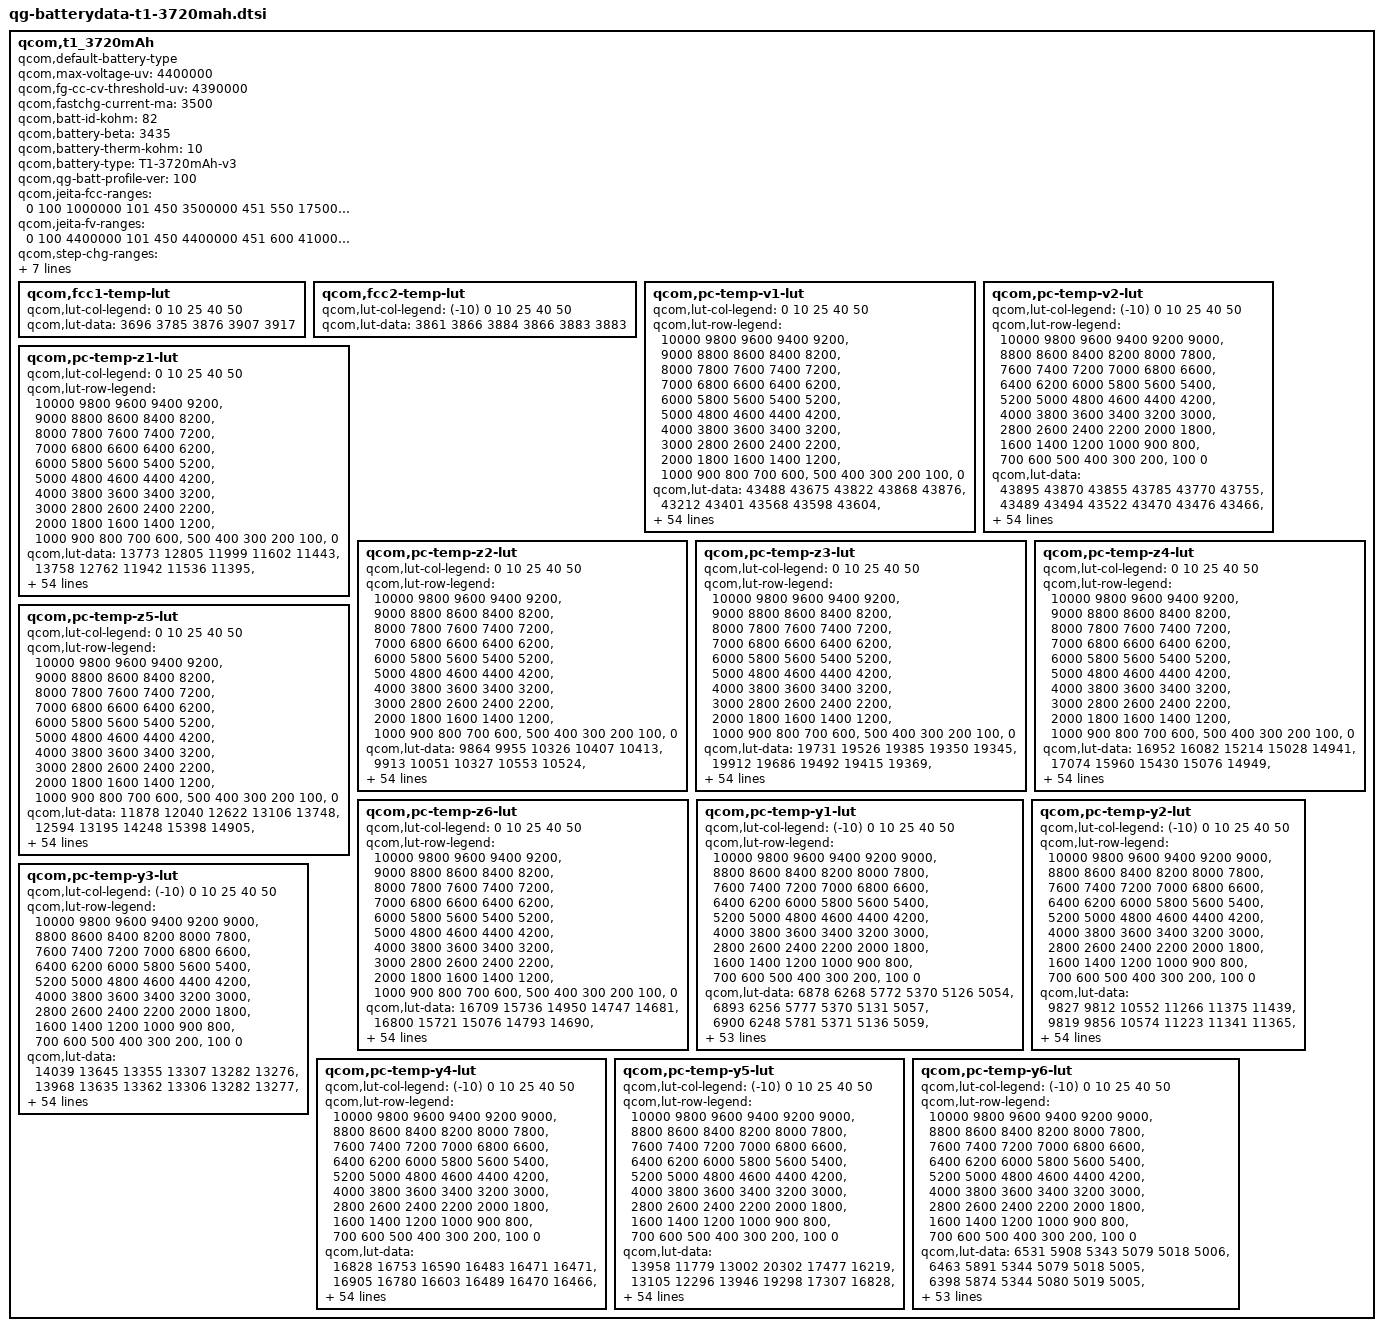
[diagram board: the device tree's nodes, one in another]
/*
 * Copyright (c) 2018, The Linux Foundation. All rights reserved.
 *
 * This program is free software; you can redistribute it and/or modify
 * it under the terms of the GNU General Public License version 2 and
 * only version 2 as published by the Free Software Foundation.
 *
 * This program is distributed in the hope that it will be useful,
 * but WITHOUT ANY WARRANTY; without even the implied warranty of
 * MERCHANTABILITY or FITNESS FOR A PARTICULAR PURPOSE.  See the
 * GNU General Public License for more details.
 */

qcom,t1_3720mAh {
	/* 4059676_TCL_T1_Veken_3820mAH_PM6150_averaged_MasterSlave_Jul23th2019 */
	qcom,default-battery-type;
	qcom,max-voltage-uv = <4400000>;
	qcom,fg-cc-cv-threshold-uv = <4390000>;
	qcom,fastchg-current-ma = <3500>;
	qcom,batt-id-kohm = <82>;
	qcom,battery-beta = <3435>;
	qcom,battery-therm-kohm = <10>;
	qcom,battery-type = "T1-3720mAh-v3";
	qcom,qg-batt-profile-ver = <100>;

	qcom,jeita-fcc-ranges = <0  100   1000000
				101  450  3500000
				451 550  1750000
				551 600  0>;
	qcom,jeita-fv-ranges = <0   100   4400000
				101  450  4400000
				451 600  4100000>;
	qcom,step-chg-ranges = <2800000  4285000  3500000
				4285001  4400000  2500000>;
	qcom,ocv-based-step-chg;

	/* COOL = 10 DegC, WARM = 45 DegC */
	qcom,jeita-soft-thresholds = <0x2aee 0xfb3>;
	/* COLD = 0 DegC, HOT = 55 DegC */
	qcom,jeita-hard-thresholds = <0x3733 0xbc2>;
	/* COOL hys = 13 DegC, WARM hys = 42 DegC */
	qcom,jeita-soft-hys-thresholds = <0x279a 0x1124>;

	qcom,jeita-soft-fcc-ua = <1500000 1500000>;
	qcom,jeita-soft-fv-uv = <4100000 4100000>;

	qcom,fcc1-temp-lut {
		qcom,lut-col-legend = <0 10 25 40 50>;
		qcom,lut-data = <3696 3785 3876 3907 3917>;
	};

	qcom,fcc2-temp-lut {
		qcom,lut-col-legend = <(-10) 0 10 25 40 50>;
		qcom,lut-data = <3861 3866 3884 3866 3883 3883>;
	};

	qcom,pc-temp-v1-lut {
		qcom,lut-col-legend = <0 10 25 40 50>;
		qcom,lut-row-legend = <10000 9800 9600 9400 9200>,
			<9000 8800 8600 8400 8200>,
			<8000 7800 7600 7400 7200>,
			<7000 6800 6600 6400 6200>,
			<6000 5800 5600 5400 5200>,
			<5000 4800 4600 4400 4200>,
			<4000 3800 3600 3400 3200>,
			<3000 2800 2600 2400 2200>,
			<2000 1800 1600 1400 1200>,
			<1000 900 800 700 600>,
			<500 400 300 200 100>,
			<0>;
		qcom,lut-data = <43488 43675 43822 43868 43876>,
			<43212 43401 43568 43598 43604>,
			<42961 43139 43318 43352 43358>,
			<42725 42893 43073 43115 43121>,
			<42495 42658 42830 42879 42885>,
			<42272 42426 42589 42641 42648>,
			<42054 42196 42352 42405 42414>,
			<41840 41973 42118 42169 42181>,
			<41632 41756 41889 41935 41950>,
			<41435 41545 41661 41706 41722>,
			<41261 41350 41438 41479 41495>,
			<41082 41179 41232 41259 41273>,
			<40859 40997 41049 41044 41054>,
			<40588 40755 40857 40836 40843>,
			<40333 40467 40609 40628 40638>,
			<40107 40227 40344 40424 40440>,
			<39907 40035 40147 40233 40250>,
			<39752 39872 40002 40058 40070>,
			<39631 39740 39864 39891 39897>,
			<39518 39629 39720 39735 39736>,
			<39399 39508 39571 39585 39585>,
			<39283 39372 39392 39400 39404>,
			<39169 39229 39179 39139 39145>,
			<39057 39074 38973 38899 38901>,
			<38949 38906 38764 38747 38754>,
			<38845 38746 38581 38629 38643>,
			<38745 38583 38484 38528 38541>,
			<38651 38446 38424 38441 38446>,
			<38563 38362 38367 38361 38357>,
			<38483 38302 38306 38281 38269>,
			<38413 38258 38249 38207 38187>,
			<38350 38229 38194 38140 38116>,
			<38297 38205 38142 38082 38056>,
			<38253 38177 38094 38028 37998>,
			<38216 38150 38053 37981 37944>,
			<38177 38121 38013 37936 37892>,
			<38139 38091 37978 37891 37839>,
			<38098 38056 37944 37847 37786>,
			<38049 38004 37894 37790 37721>,
			<37993 37925 37807 37707 37638>,
			<37918 37831 37701 37606 37539>,
			<37801 37716 37590 37497 37430>,
			<37665 37580 37462 37370 37303>,
			<37508 37416 37302 37212 37145>,
			<37355 37267 37153 37065 37001>,
			<37240 37165 37063 36974 36913>,
			<37206 37139 37036 36950 36892>,
			<37178 37116 37024 36935 36877>,
			<37150 37094 37005 36918 36859>,
			<37116 37062 36968 36876 36809>,
			<36957 36892 36759 36648 36563>,
			<36524 36466 36337 36221 36133>,
			<35951 35902 35770 35650 35561>,
			<35180 35132 34989 34866 34777>,
			<33966 33932 33771 33650 33562>,
			<30000 30000 30000 30000 30000>;
	};

	qcom,pc-temp-v2-lut {
		qcom,lut-col-legend = <(-10) 0 10 25 40 50>;
		qcom,lut-row-legend = <10000 9800 9600 9400 9200 9000>,
			<8800 8600 8400 8200 8000 7800>,
			<7600 7400 7200 7000 6800 6600>,
			<6400 6200 6000 5800 5600 5400>,
			<5200 5000 4800 4600 4400 4200>,
			<4000 3800 3600 3400 3200 3000>,
			<2800 2600 2400 2200 2000 1800>,
			<1600 1400 1200 1000 900 800>,
			<700 600 500 400 300 200>,
			<100 0>;
		qcom,lut-data = <43895 43870 43855 43785 43770 43755>,
			<43489 43494 43522 43470 43476 43466>,
			<43125 43153 43216 43177 43200 43194>,
			<42810 42855 42942 42911 42942 42939>,
			<42534 42592 42698 42670 42704 42702>,
			<42282 42344 42459 42434 42469 42469>,
			<42058 42105 42218 42199 42235 42235>,
			<41845 41873 41982 41968 42003 42004>,
			<41604 41639 41755 41742 41774 41776>,
			<41337 41400 41535 41521 41548 41550>,
			<41131 41195 41325 41304 41326 41327>,
			<41020 41046 41129 41091 41110 41109>,
			<40912 40899 40937 40880 40897 40895>,
			<40647 40683 40741 40671 40692 40690>,
			<40145 40394 40541 40463 40491 40490>,
			<39768 40106 40312 40264 40298 40297>,
			<39569 39815 40020 40069 40110 40109>,
			<39409 39553 39741 39888 39930 39929>,
			<39247 39374 39553 39736 39764 39763>,
			<39094 39237 39403 39604 39608 39607>,
			<38946 39090 39236 39437 39428 39429>,
			<38800 38921 39042 39189 39206 39215>,
			<38662 38757 38860 38938 38988 39004>,
			<38532 38619 38706 38758 38801 38814>,
			<38410 38494 38568 38607 38632 38639>,
			<38306 38374 38447 38479 38496 38500>,
			<38219 38253 38340 38370 38386 38390>,
			<38143 38151 38240 38273 38289 38292>,
			<38073 38080 38140 38184 38199 38201>,
			<38009 38022 38045 38102 38118 38118>,
			<37949 37969 37968 38029 38046 38043>,
			<37891 37920 37902 37959 37981 37973>,
			<37835 37873 37850 37897 37917 37909>,
			<37778 37826 37809 37841 37850 37851>,
			<37723 37782 37775 37792 37783 37793>,
			<37668 37736 37741 37740 37712 37712>,
			<37615 37691 37708 37688 37638 37603>,
			<37561 37642 37669 37631 37560 37500>,
			<37503 37584 37617 37566 37481 37412>,
			<37444 37517 37554 37495 37399 37329>,
			<37385 37439 37477 37414 37316 37247>,
			<37326 37340 37381 37319 37228 37165>,
			<37264 37236 37262 37204 37115 37053>,
			<37195 37133 37122 37066 36980 36916>,
			<37108 37039 36985 36928 36849 36791>,
			<36996 36951 36900 36873 36807 36753>,
			<36931 36912 36874 36857 36795 36741>,
			<36865 36873 36848 36842 36782 36729>,
			<36783 36824 36811 36815 36757 36703>,
			<36645 36733 36729 36746 36678 36609>,
			<36408 36516 36519 36494 36379 36292>,
			<36007 36090 36071 36013 35881 35794>,
			<35411 35465 35433 35386 35236 35146>,
			<34537 34583 34550 34535 34349 34256>,
			<33123 33197 33220 33227 32993 32912>,
			<29037 28523 28866 28088 28343 28620>;
	};

	qcom,pc-temp-z1-lut {
		qcom,lut-col-legend = <0 10 25 40 50>;
		qcom,lut-row-legend = <10000 9800 9600 9400 9200>,
			<9000 8800 8600 8400 8200>,
			<8000 7800 7600 7400 7200>,
			<7000 6800 6600 6400 6200>,
			<6000 5800 5600 5400 5200>,
			<5000 4800 4600 4400 4200>,
			<4000 3800 3600 3400 3200>,
			<3000 2800 2600 2400 2200>,
			<2000 1800 1600 1400 1200>,
			<1000 900 800 700 600>,
			<500 400 300 200 100>,
			<0>;
		qcom,lut-data = <13773 12805 11999 11602 11443>,
			<13758 12762 11942 11536 11395>,
			<13745 12734 11919 11526 11387>,
			<13732 12733 11903 11519 11383>,
			<13732 12733 11896 11512 11378>,
			<13740 12729 11891 11503 11373>,
			<13735 12700 11885 11497 11370>,
			<13709 12674 11875 11494 11370>,
			<13676 12672 11869 11493 11371>,
			<13661 12675 11870 11492 11371>,
			<13662 12677 11873 11494 11371>,
			<13666 12673 11877 11496 11371>,
			<13664 12664 11884 11499 11373>,
			<13653 12643 11887 11503 11376>,
			<13638 12614 11875 11504 11379>,
			<13594 12605 11854 11504 11381>,
			<13543 12605 11850 11505 11383>,
			<13527 12608 11860 11508 11387>,
			<13525 12620 11870 11511 11391>,
			<13524 12642 11878 11515 11393>,
			<13510 12651 11885 11519 11394>,
			<13487 12651 11888 11522 11395>,
			<13483 12651 11891 11523 11395>,
			<13490 12658 11894 11525 11396>,
			<13495 12675 11897 11526 11396>,
			<13492 12683 11901 11528 11398>,
			<13486 12680 11904 11530 11400>,
			<13483 12677 11908 11535 11403>,
			<13501 12677 11910 11540 11407>,
			<13523 12680 11911 11543 11410>,
			<13525 12684 11912 11547 11413>,
			<13516 12695 11917 11551 11416>,
			<13511 12707 11927 11556 11418>,
			<13529 12709 11934 11560 11421>,
			<13560 12707 11937 11563 11424>,
			<13571 12708 11941 11566 11427>,
			<13573 12724 11945 11569 11428>,
			<13576 12745 11950 11571 11428>,
			<13596 12747 11955 11573 11428>,
			<13631 12742 11963 11576 11429>,
			<13642 12740 11970 11578 11431>,
			<13617 12741 11974 11580 11431>,
			<13603 12746 11975 11581 11432>,
			<13605 12769 11979 11581 11431>,
			<13588 12770 11979 11582 11430>,
			<13686 12758 11991 11583 11431>,
			<13900 12780 11987 11581 11429>,
			<13619 12776 11987 11583 11429>,
			<13868 12768 11975 11583 11430>,
			<13611 12774 11976 11585 11432>,
			<13612 12770 11985 11590 11436>,
			<13634 12824 12002 11598 11443>,
			<13625 12818 12017 11607 11451>,
			<13702 12834 12028 11623 11463>,
			<13702 12834 12028 11623 11463>,
			<13702 12834 12028 11623 11463>;
	};

	qcom,pc-temp-z2-lut {
		qcom,lut-col-legend = <0 10 25 40 50>;
		qcom,lut-row-legend = <10000 9800 9600 9400 9200>,
			<9000 8800 8600 8400 8200>,
			<8000 7800 7600 7400 7200>,
			<7000 6800 6600 6400 6200>,
			<6000 5800 5600 5400 5200>,
			<5000 4800 4600 4400 4200>,
			<4000 3800 3600 3400 3200>,
			<3000 2800 2600 2400 2200>,
			<2000 1800 1600 1400 1200>,
			<1000 900 800 700 600>,
			<500 400 300 200 100>,
			<0>;
		qcom,lut-data = <9864 9955 10326 10407 10413>,
			<9913 10051 10327 10553 10524>,
			<9974 10095 10329 10564 10644>,
			<10027 10084 10318 10555 10631>,
			<10039 10059 10295 10531 10610>,
			<10034 10046 10260 10457 10553>,
			<10027 10041 10229 10407 10507>,
			<10012 10036 10194 10410 10505>,
			<9988 10027 10173 10420 10510>,
			<9973 10015 10177 10427 10512>,
			<9967 10009 10189 10440 10511>,
			<9960 10007 10203 10452 10511>,
			<9939 10004 10222 10465 10522>,
			<9892 9990 10244 10481 10535>,
			<9861 9965 10268 10497 10524>,
			<9851 9957 10292 10512 10478>,
			<9846 9972 10307 10515 10453>,
			<9848 9995 10317 10472 10450>,
			<9864 10029 10326 10433 10453>,
			<9881 10073 10332 10442 10468>,
			<9894 10088 10339 10475 10501>,
			<9905 10084 10353 10512 10561>,
			<9908 10079 10387 10564 10748>,
			<9903 10085 10405 10598 10910>,
			<9898 10102 10375 10531 10803>,
			<9898 10109 10334 10395 10535>,
			<9898 10105 10320 10377 10461>,
			<9899 10101 10312 10499 10543>,
			<9906 10106 10310 10598 10619>,
			<9918 10125 10354 10621 10638>,
			<9929 10137 10406 10635 10648>,
			<9938 10140 10402 10619 10634>,
			<9950 10143 10377 10533 10547>,
			<9966 10150 10368 10485 10492>,
			<9986 10160 10372 10519 10525>,
			<10011 10172 10378 10573 10589>,
			<10049 10184 10385 10607 10657>,
			<10074 10196 10398 10632 10741>,
			<10034 10209 10417 10660 10795>,
			<9943 10222 10459 10704 10829>,
			<9912 10238 10491 10736 10848>,
			<9948 10260 10493 10730 10810>,
			<9975 10286 10494 10715 10728>,
			<9989 10309 10505 10727 10757>,
			<9968 10473 10574 10740 10749>,
			<10000 10658 10643 10672 10639>,
			<9727 10607 10641 10664 10650>,
			<9606 10627 10724 10645 10614>,
			<9741 10652 10856 10640 10653>,
			<9627 10720 10809 10731 10778>,
			<9633 10711 10819 10814 10615>,
			<9571 10592 10833 10686 10450>,
			<9768 10438 10888 10617 10357>,
			<9636 10298 10860 10517 10290>,
			<9636 10298 10860 10517 10290>,
			<9636 10298 10860 10517 10290>;
	};

	qcom,pc-temp-z3-lut {
		qcom,lut-col-legend = <0 10 25 40 50>;
		qcom,lut-row-legend = <10000 9800 9600 9400 9200>,
			<9000 8800 8600 8400 8200>,
			<8000 7800 7600 7400 7200>,
			<7000 6800 6600 6400 6200>,
			<6000 5800 5600 5400 5200>,
			<5000 4800 4600 4400 4200>,
			<4000 3800 3600 3400 3200>,
			<3000 2800 2600 2400 2200>,
			<2000 1800 1600 1400 1200>,
			<1000 900 800 700 600>,
			<500 400 300 200 100>,
			<0>;
		qcom,lut-data = <19731 19526 19385 19350 19345>,
			<19912 19686 19492 19415 19369>,
			<19924 19776 19533 19450 19414>,
			<19914 19792 19555 19462 19432>,
			<19895 19800 19565 19467 19442>,
			<19851 19802 19571 19469 19447>,
			<19822 19799 19572 19470 19450>,
			<19827 19793 19567 19467 19444>,
			<19840 19786 19561 19461 19430>,
			<19846 19774 19553 19452 19418>,
			<19846 19761 19542 19439 19409>,
			<19846 19741 19529 19427 19402>,
			<19863 19728 19512 19417 19396>,
			<19927 19733 19503 19408 19389>,
			<19969 19747 19503 19403 19380>,
			<19976 19751 19503 19400 19369>,
			<19976 19728 19500 19396 19361>,
			<19965 19692 19480 19388 19355>,
			<19928 19652 19465 19380 19350>,
			<19896 19608 19461 19376 19347>,
			<19882 19595 19459 19372 19344>,
			<19873 19612 19464 19372 19344>,
			<19872 19637 19486 19391 19361>,
			<19886 19661 19499 19408 19377>,
			<19904 19687 19495 19398 19367>,
			<19914 19698 19488 19377 19341>,
			<19923 19699 19479 19368 19334>,
			<19926 19700 19467 19365 19335>,
			<19923 19699 19462 19364 19339>,
			<19917 19696 19464 19381 19358>,
			<19910 19691 19468 19407 19390>,
			<19897 19680 19475 19412 19395>,
			<19881 19666 19487 19412 19387>,
			<19856 19655 19491 19411 19377>,
			<19824 19644 19488 19405 19370>,
			<19794 19634 19484 19395 19364>,
			<19770 19622 19478 19390 19360>,
			<19736 19612 19470 19386 19357>,
			<19623 19608 19466 19383 19356>,
			<19438 19607 19463 19380 19355>,
			<19372 19604 19461 19377 19354>,
			<19375 19588 19457 19375 19353>,
			<19376 19569 19452 19373 19350>,
			<19372 19560 19448 19371 19350>,
			<19353 19509 19438 19366 19348>,
			<19345 19445 19413 19356 19340>,
			<19298 19338 19413 19355 19333>,
			<19276 19313 19365 19348 19329>,
			<19298 19304 19344 19345 19326>,
			<19271 19303 19355 19338 19317>,
			<19270 19317 19379 19329 19336>,
			<19278 19324 19378 19337 19343>,
			<19351 19318 19343 19339 19348>,
			<19358 19315 19327 19340 19348>,
			<19358 19315 19327 19340 19348>,
			<19358 19315 19327 19340 19348>;
	};

	qcom,pc-temp-z4-lut {
		qcom,lut-col-legend = <0 10 25 40 50>;
		qcom,lut-row-legend = <10000 9800 9600 9400 9200>,
			<9000 8800 8600 8400 8200>,
			<8000 7800 7600 7400 7200>,
			<7000 6800 6600 6400 6200>,
			<6000 5800 5600 5400 5200>,
			<5000 4800 4600 4400 4200>,
			<4000 3800 3600 3400 3200>,
			<3000 2800 2600 2400 2200>,
			<2000 1800 1600 1400 1200>,
			<1000 900 800 700 600>,
			<500 400 300 200 100>,
			<0>;
		qcom,lut-data = <16952 16082 15214 15028 14941>,
			<17074 15960 15430 15076 14949>,
			<16901 15822 15321 15080 14979>,
			<16560 15650 15174 15000 14926>,
			<16309 15465 15081 14942 14881>,
			<16128 15327 15006 14902 14846>,
			<15970 15222 14950 14868 14817>,
			<15827 15139 14907 14832 14796>,
			<15701 15077 14872 14801 14780>,
			<15593 15027 14841 14787 14770>,
			<15501 14983 14814 14781 14763>,
			<15420 14941 14796 14774 14756>,
			<15348 14905 14781 14766 14748>,
			<15284 14872 14770 14757 14739>,
			<15233 14844 14767 14747 14734>,
			<15195 14833 14765 14736 14729>,
			<15163 14830 14759 14726 14724>,
			<15133 14828 14739 14717 14717>,
			<15104 14831 14721 14708 14709>,
			<15075 14837 14711 14702 14702>,
			<15042 14838 14704 14698 14695>,
			<15007 14804 14708 14701 14696>,
			<14970 14769 14735 14761 14754>,
			<14929 14767 14768 14826 14822>,
			<14894 14770 14829 14855 14850>,
			<14869 14775 14890 14875 14869>,
			<14850 14815 14893 14878 14871>,
			<14838 14856 14875 14864 14855>,
			<14831 14857 14853 14844 14829>,
			<14827 14843 14829 14807 14787>,
			<14823 14827 14801 14760 14735>,
			<14819 14809 14773 14732 14712>,
			<14817 14790 14742 14713 14701>,
			<14819 14775 14724 14705 14697>,
			<14825 14763 14714 14703 14698>,
			<14830 14753 14708 14702 14700>,
			<14836 14745 14703 14703 14703>,
			<14847 14739 14700 14706 14709>,
			<14940 14733 14699 14710 14716>,
			<15129 14727 14710 14722 14723>,
			<15197 14725 14720 14731 14728>,
			<15177 14732 14715 14727 14724>,
			<15150 14738 14708 14717 14715>,
			<15122 14735 14708 14720 14717>,
			<15028 14733 14700 14715 14713>,
			<14983 14751 14684 14691 14690>,
			<15026 14868 14670 14678 14682>,
			<15042 14886 14708 14663 14664>,
			<15013 14890 14720 14646 14642>,
			<15033 14885 14704 14652 14648>,
			<15027 14875 14702 14699 14668>,
			<15044 14887 14714 14700 14670>,
			<14995 14905 14760 14701 14666>,
			<15011 14921 14784 14704 14668>,
			<15011 14921 14784 14704 14668>,
			<15011 14921 14784 14704 14668>;
	};

	qcom,pc-temp-z5-lut {
		qcom,lut-col-legend = <0 10 25 40 50>;
		qcom,lut-row-legend = <10000 9800 9600 9400 9200>,
			<9000 8800 8600 8400 8200>,
			<8000 7800 7600 7400 7200>,
			<7000 6800 6600 6400 6200>,
			<6000 5800 5600 5400 5200>,
			<5000 4800 4600 4400 4200>,
			<4000 3800 3600 3400 3200>,
			<3000 2800 2600 2400 2200>,
			<2000 1800 1600 1400 1200>,
			<1000 900 800 700 600>,
			<500 400 300 200 100>,
			<0>;
		qcom,lut-data = <11878 12040 12622 13106 13748>,
			<12594 13195 14248 15398 14905>,
			<12906 13971 14941 16123 16223>,
			<13096 14321 15450 16487 17109>,
			<13193 14556 15958 16721 17789>,
			<13272 14855 16434 16897 18433>,
			<13357 15240 16807 17127 18794>,
			<13523 15589 17111 17753 18764>,
			<13758 15848 17413 18490 18621>,
			<13893 16067 18005 18550 18505>,
			<13939 16282 18746 18202 18292>,
			<13985 16461 19021 17983 18220>,
			<14181 16725 19097 17962 18291>,
			<14723 18073 19208 17978 18315>,
			<15159 20666 20188 18225 18197>,
			<15427 21541 21660 18927 17859>,
			<15642 20508 21775 19389 17716>,
			<15593 18989 20798 19706 17940>,
			<15167 17523 20201 20131 18299>,
			<14854 15992 21009 20576 18674>,
			<14952 15621 23115 21132 19416>,
			<15262 17551 28920 22845 20992>,
			<15760 21085 44150 32356 28056>,
			<16995 27959 52105 40239 34440>,
			<18680 39576 46833 35443 30648>,
			<20591 44857 38370 24637 20794>,
			<22883 45454 32152 19713 16713>,
			<24825 45620 26183 17570 15615>,
			<26656 44898 23205 16682 15157>,
			<28088 42670 22268 17852 17061>,
			<28448 39996 21780 20395 21015>,
			<28327 36399 22905 23209 23309>,
			<27903 32758 26895 26924 24741>,
			<26038 30539 30549 29520 25987>,
			<23012 28906 33985 30878 27557>,
			<20886 27633 36235 31693 28851>,
			<19499 26427 35985 31594 28836>,
			<18029 25589 34876 30835 28026>,
			<15450 26096 33856 29706 26896>,
			<12348 28363 33005 27000 24792>,
			<11328 29548 32052 24196 22647>,
			<11400 26011 30575 23118 21616>,
			<11488 23093 28819 22430 20927>,
			<11575 23320 27451 21305 20455>,
			<11912 21782 27541 21031 20134>,
			<12074 17218 24599 21150 20025>,
			<11528 12520 25447 21843 18949>,
			<11333 11990 16266 21212 19772>,
			<11522 11835 14309 22752 23084>,
			<11307 11841 15395 20669 19858>,
			<11369 12191 17347 15379 17887>,
			<11442 12228 16179 15084 17462>,
			<11971 11959 13623 14774 17720>,
			<11867 11766 12690 14514 16872>,
			<11867 11766 12690 14514 16872>,
			<11867 11766 12690 14514 16872>;
	};

	qcom,pc-temp-z6-lut {
		qcom,lut-col-legend = <0 10 25 40 50>;
		qcom,lut-row-legend = <10000 9800 9600 9400 9200>,
			<9000 8800 8600 8400 8200>,
			<8000 7800 7600 7400 7200>,
			<7000 6800 6600 6400 6200>,
			<6000 5800 5600 5400 5200>,
			<5000 4800 4600 4400 4200>,
			<4000 3800 3600 3400 3200>,
			<3000 2800 2600 2400 2200>,
			<2000 1800 1600 1400 1200>,
			<1000 900 800 700 600>,
			<500 400 300 200 100>,
			<0>;
		qcom,lut-data = <16709 15736 14950 14747 14681>,
			<16800 15721 15076 14793 14690>,
			<16707 15695 15043 14806 14719>,
			<16514 15628 14993 14780 14708>,
			<16361 15525 14956 14759 14697>,
			<16238 15447 14922 14743 14686>,
			<16136 15386 14895 14727 14674>,
			<16059 15336 14872 14710 14661>,
			<15997 15296 14852 14693 14647>,
			<15940 15263 14833 14681 14637>,
			<15884 15231 14816 14672 14629>,
			<15837 15197 14802 14663 14622>,
			<15811 15168 14788 14654 14614>,
			<15794 15150 14778 14646 14607>,
			<15778 15137 14772 14639 14600>,
			<15758 15123 14768 14632 14593>,
			<15735 15107 14760 14625 14586>,
			<15707 15091 14744 14617 14579>,
			<15671 15075 14731 14610 14574>,
			<15637 15060 14726 14605 14569>,
			<15607 15055 14724 14602 14565>,
			<15580 15055 14728 14604 14566>,
			<15569 15054 14750 14643 14603>,
			<15564 15059 14774 14677 14639>,
			<15561 15076 14800 14680 14640>,
			<15560 15095 14821 14680 14638>,
			<15559 15116 14821 14680 14635>,
			<15558 15132 14808 14673 14630>,
			<15557 15132 14796 14665 14623>,
			<15556 15127 14787 14659 14617>,
			<15553 15119 14780 14653 14611>,
			<15547 15108 14773 14646 14605>,
			<15539 15095 14767 14639 14596>,
			<15530 15085 14762 14633 14589>,
			<15520 15076 14758 14628 14585>,
			<15512 15069 14754 14624 14583>,
			<15505 15064 14750 14622 14582>,
			<15499 15060 14745 14621 14583>,
			<15492 15060 14745 14621 14584>,
			<15486 15061 14750 14624 14586>,
			<15482 15062 14754 14627 14588>,
			<15480 15061 14752 14625 14585>,
			<15477 15059 14747 14619 14580>,
			<15470 15058 14748 14619 14581>,
			<15430 15039 14742 14615 14578>,
			<15408 15018 14724 14600 14564>,
			<15405 15013 14718 14594 14557>,
			<15402 15009 14710 14584 14546>,
			<15401 15007 14705 14575 14534>,
			<15403 15008 14706 14574 14534>,
			<15412 15018 14719 14591 14553>,
			<15432 15034 14728 14598 14559>,
			<15456 15050 14734 14601 14563>,
			<15489 15069 14743 14607 14567>,
			<15489 15069 14743 14607 14567>,
			<15489 15069 14743 14607 14567>;
	};

	qcom,pc-temp-y1-lut {
		qcom,lut-col-legend = <(-10) 0 10 25 40 50>;
		qcom,lut-row-legend = <10000 9800 9600 9400 9200 9000>,
			<8800 8600 8400 8200 8000 7800>,
			<7600 7400 7200 7000 6800 6600>,
			<6400 6200 6000 5800 5600 5400>,
			<5200 5000 4800 4600 4400 4200>,
			<4000 3800 3600 3400 3200 3000>,
			<2800 2600 2400 2200 2000 1800>,
			<1600 1400 1200 1000 900 800>,
			<700 600 500 400 300 200>,
			<100 0>;
		qcom,lut-data = <6878 6268 5772 5370 5126 5054>,
			<6893 6256 5777 5370 5131 5057>,
			<6900 6248 5781 5371 5136 5059>,
			<6900 6242 5784 5371 5139 5061>,
			<6897 6239 5786 5370 5142 5061>,
			<6893 6238 5786 5369 5143 5061>,
			<6883 6241 5780 5366 5143 5060>,
			<6870 6246 5773 5363 5142 5059>,
			<6865 6247 5774 5361 5140 5058>,
			<6867 6247 5781 5361 5138 5058>,
			<6870 6247 5784 5361 5137 5058>,
			<6872 6246 5775 5361 5137 5056>,
			<6873 6244 5763 5362 5137 5055>,
			<6876 6246 5765 5360 5136 5055>,
			<6880 6248 5775 5357 5135 5055>,
			<6885 6250 5781 5355 5135 5055>,
			<6896 6251 5785 5363 5137 5055>,
			<6907 6251 5788 5371 5140 5056>,
			<6901 6251 5787 5371 5140 5056>,
			<6879 6252 5783 5369 5140 5056>,
			<6864 6255 5783 5368 5140 5057>,
			<6858 6265 5788 5370 5140 5058>,
			<6853 6273 5791 5371 5141 5058>,
			<6855 6268 5787 5371 5142 5059>,
			<6865 6255 5783 5371 5143 5060>,
			<6875 6244 5781 5373 5145 5061>,
			<6892 6232 5780 5376 5146 5062>,
			<6905 6223 5780 5379 5148 5064>,
			<6885 6218 5783 5381 5150 5066>,
			<6843 6215 5786 5382 5152 5068>,
			<6831 6216 5786 5384 5155 5070>,
			<6841 6225 5782 5388 5158 5072>,
			<6851 6232 5781 5391 5160 5074>,
			<6853 6230 5783 5393 5163 5076>,
			<6854 6225 5788 5395 5165 5077>,
			<6854 6222 5791 5396 5166 5079>,
			<6840 6216 5790 5395 5168 5080>,
			<6826 6210 5788 5394 5170 5080>,
			<6820 6224 5788 5394 5171 5080>,
			<6815 6244 5788 5393 5172 5080>,
			<6819 6241 5786 5394 5173 5081>,
			<6834 6217 5785 5398 5173 5083>,
			<6833 6217 5788 5403 5175 5084>,
			<6824 6228 5801 5409 5177 5087>,
			<6875 6244 5805 5416 5181 5090>,
			<6932 6265 5816 5427 5185 5091>,
			<6897 6247 5817 5423 5188 5093>,
			<6875 6258 5819 5423 5188 5092>,
			<6884 6270 5799 5432 5188 5092>,
			<6931 6269 5813 5433 5190 5091>,
			<6939 6289 5804 5431 5189 5093>,
			<6879 6292 5836 5436 5194 5099>,
			<6905 6289 5837 5462 5202 5105>,
			<6974 6315 5854 5484 5216 5115>,
			<6974 6315 5854 5484 5216 5115>,
			<6974 6315 5854 5484 5216 5115>;
	};

	qcom,pc-temp-y2-lut {
		qcom,lut-col-legend = <(-10) 0 10 25 40 50>;
		qcom,lut-row-legend = <10000 9800 9600 9400 9200 9000>,
			<8800 8600 8400 8200 8000 7800>,
			<7600 7400 7200 7000 6800 6600>,
			<6400 6200 6000 5800 5600 5400>,
			<5200 5000 4800 4600 4400 4200>,
			<4000 3800 3600 3400 3200 3000>,
			<2800 2600 2400 2200 2000 1800>,
			<1600 1400 1200 1000 900 800>,
			<700 600 500 400 300 200>,
			<100 0>;
		qcom,lut-data = <9827 9812 10552 11266 11375 11439>,
			<9819 9856 10574 11223 11341 11365>,
			<9828 9905 10589 11182 11292 11288>,
			<9849 9953 10599 11143 11239 11217>,
			<9881 9993 10604 11108 11196 11164>,
			<9920 10018 10606 11077 11173 11139>,
			<9967 10030 10599 11049 11165 11138>,
			<10027 10040 10591 11024 11159 11145>,
			<10107 10075 10594 11008 11154 11147>,
			<10217 10164 10608 10995 11147 11151>,
			<10303 10260 10618 10991 11144 11149>,
			<10363 10363 10621 10993 11144 11143>,
			<10403 10447 10624 11000 11147 11139>,
			<10295 10469 10670 11023 11155 11147>,
			<9903 10476 10788 11078 11176 11171>,
			<9705 10489 10833 11108 11208 11197>,
			<9691 10522 10822 11111 11281 11227>,
			<9684 10570 10812 11113 11356 11271>,
			<9680 10643 10825 11138 11403 11390>,
			<9678 10742 10862 11190 11442 11579>,
			<9677 10784 10886 11207 11452 11635>,
			<9676 10790 10898 11186 11445 11623>,
			<9675 10793 10910 11166 11433 11602>,
			<9674 10789 10929 11169 11379 11513>,
			<9672 10771 10952 11182 11295 11371>,
			<9671 10701 10974 11196 11278 11349>,
			<9670 10195 10999 11213 11311 11426>,
			<9669 9743 11015 11234 11357 11483>,
			<9669 9707 11017 11261 11412 11510>,
			<9668 9697 11016 11290 11474 11560>,
			<9668 9692 11019 11299 11518 11607>,
			<9667 9689 11024 11300 11558 11657>,
			<9667 9686 11027 11300 11575 11687>,
			<9666 9683 11010 11300 11573 11715>,
			<9665 9681 10980 11298 11566 11744>,
			<9664 9678 10956 11292 11547 11715>,
			<9664 9675 10935 11271 11485 11580>,
			<9663 9672 10910 11252 11443 11469>,
			<9662 9670 10882 11242 11442 11401>,
			<9662 9668 10848 11234 11441 11357>,
			<9662 9666 10802 11221 11426 11366>,
			<9661 9665 10740 11199 11402 11414>,
			<9661 9663 10672 11169 11397 11402>,
			<9660 9662 10450 11121 11385 11336>,
			<9660 9661 9923 11074 11228 11205>,
			<9660 9661 9786 11070 11175 11022>,
			<9659 9660 9733 11046 11176 11048>,
			<9659 9659 9702 11030 11168 11103>,
			<9658 9658 9693 11012 11168 11101>,
			<9658 9658 9684 10996 11169 11123>,
			<9658 9658 9678 10977 11169 10998>,
			<9657 9657 9670 10894 11103 10927>,
			<9656 9656 9664 10791 10996 10911>,
			<9654 9655 9659 10723 10942 10836>,
			<9654 9655 9659 10723 10942 10836>,
			<9654 9655 9659 10723 10942 10836>;
	};

	qcom,pc-temp-y3-lut {
		qcom,lut-col-legend = <(-10) 0 10 25 40 50>;
		qcom,lut-row-legend = <10000 9800 9600 9400 9200 9000>,
			<8800 8600 8400 8200 8000 7800>,
			<7600 7400 7200 7000 6800 6600>,
			<6400 6200 6000 5800 5600 5400>,
			<5200 5000 4800 4600 4400 4200>,
			<4000 3800 3600 3400 3200 3000>,
			<2800 2600 2400 2200 2000 1800>,
			<1600 1400 1200 1000 900 800>,
			<700 600 500 400 300 200>,
			<100 0>;
		qcom,lut-data = <14039 13645 13355 13307 13282 13276>,
			<13968 13635 13362 13306 13282 13277>,
			<13896 13624 13370 13305 13283 13279>,
			<13827 13612 13377 13305 13284 13280>,
			<13770 13598 13384 13305 13285 13281>,
			<13729 13585 13388 13305 13286 13283>,
			<13705 13566 13390 13306 13288 13284>,
			<13686 13550 13391 13307 13289 13285>,
			<13656 13548 13391 13310 13290 13287>,
			<13616 13548 13390 13314 13291 13288>,
			<13579 13548 13390 13317 13292 13289>,
			<13545 13501 13394 13317 13296 13290>,
			<13520 13445 13399 13317 13300 13290>,
			<13516 13443 13395 13317 13301 13292>,
			<13519 13456 13383 13315 13301 13297>,
			<13520 13462 13379 13314 13301 13298>,
			<13514 13450 13379 13315 13300 13297>,
			<13506 13434 13380 13317 13300 13296>,
			<13500 13426 13379 13319 13299 13296>,
			<13494 13422 13374 13322 13295 13297>,
			<13492 13415 13369 13322 13292 13296>,
			<13495 13398 13362 13318 13292 13291>,
			<13499 13384 13355 13312 13291 13285>,
			<13493 13385 13351 13308 13288 13281>,
			<13476 13387 13347 13305 13285 13278>,
			<13470 13386 13345 13303 13283 13278>,
			<13476 13367 13343 13303 13283 13278>,
			<13486 13346 13342 13302 13282 13279>,
			<13495 13343 13339 13303 13283 13279>,
			<13506 13348 13335 13304 13283 13278>,
			<13518 13352 13332 13305 13285 13278>,
			<13532 13360 13327 13305 13287 13278>,
			<13549 13368 13325 13305 13288 13278>,
			<13567 13377 13329 13305 13288 13280>,
			<13587 13394 13335 13306 13287 13282>,
			<13613 13411 13340 13307 13287 13282>,
			<13648 13428 13346 13307 13287 13280>,
			<13686 13448 13350 13307 13286 13279>,
			<13721 13473 13352 13306 13286 13278>,
			<13757 13503 13354 13305 13286 13278>,
			<13799 13533 13356 13305 13286 13279>,
			<13851 13562 13357 13306 13286 13283>,
			<13905 13596 13358 13307 13287 13283>,
			<13958 13638 13358 13306 13287 13281>,
			<13985 13672 13353 13304 13283 13279>,
			<13950 13667 13368 13305 13287 13285>,
			<14003 13713 13387 13307 13289 13287>,
			<14075 13770 13407 13312 13295 13293>,
			<14142 13832 13431 13317 13302 13296>,
			<14208 13892 13449 13324 13304 13295>,
			<14289 13946 13468 13320 13297 13288>,
			<14392 14025 13503 13319 13294 13288>,
			<14538 14137 13593 13331 13302 13294>,
			<14959 14268 13762 13344 13308 13300>,
			<14959 14268 13762 13344 13308 13300>,
			<14959 14268 13762 13344 13308 13300>;
	};

	qcom,pc-temp-y4-lut {
		qcom,lut-col-legend = <(-10) 0 10 25 40 50>;
		qcom,lut-row-legend = <10000 9800 9600 9400 9200 9000>,
			<8800 8600 8400 8200 8000 7800>,
			<7600 7400 7200 7000 6800 6600>,
			<6400 6200 6000 5800 5600 5400>,
			<5200 5000 4800 4600 4400 4200>,
			<4000 3800 3600 3400 3200 3000>,
			<2800 2600 2400 2200 2000 1800>,
			<1600 1400 1200 1000 900 800>,
			<700 600 500 400 300 200>,
			<100 0>;
		qcom,lut-data = <16828 16753 16590 16483 16471 16471>,
			<16905 16780 16603 16489 16470 16466>,
			<16958 16807 16617 16494 16470 16463>,
			<16993 16832 16630 16499 16470 16461>,
			<17011 16854 16641 16503 16470 16459>,
			<17016 16870 16649 16508 16471 16459>,
			<16994 16882 16652 16512 16473 16459>,
			<16965 16890 16655 16516 16476 16461>,
			<16963 16879 16663 16520 16480 16463>,
			<16975 16829 16679 16523 16486 16466>,
			<16998 16806 16696 16528 16490 16470>,
			<17133 16961 16710 16537 16492 16477>,
			<17288 17149 16727 16549 16495 16484>,
			<17237 17133 16771 16567 16501 16488>,
			<16998 16997 16848 16594 16515 16490>,
			<16886 16874 16869 16617 16530 16494>,
			<16888 16768 16764 16634 16544 16507>,
			<16891 16697 16661 16649 16560 16523>,
			<16889 16694 16654 16664 16588 16543>,
			<16881 16698 16653 16678 16622 16565>,
			<16869 16699 16648 16678 16628 16570>,
			<16838 16687 16614 16606 16585 16555>,
			<16811 16668 16581 16527 16535 16533>,
			<16811 16642 16569 16502 16502 16505>,
			<16816 16608 16561 16487 16475 16474>,
			<16818 16601 16556 16484 16470 16467>,
			<16814 16645 16552 16486 16474 16469>,
			<16810 16693 16548 16489 16479 16471>,
			<16807 16704 16539 16492 16487 16479>,
			<16805 16706 16530 16497 16497 16492>,
			<16805 16705 16531 16503 16508 16504>,
			<16806 16704 16540 16510 16520 16518>,
			<16808 16705 16546 16517 16526 16529>,
			<16811 16706 16548 16523 16527 16537>,
			<16816 16706 16550 16528 16526 16542>,
			<16819 16708 16555 16529 16523 16535>,
			<16821 16714 16567 16525 16508 16501>,
			<16824 16719 16579 16520 16495 16481>,
			<16835 16720 16589 16517 16487 16477>,
			<16854 16720 16598 16514 16481 16475>,
			<16870 16718 16604 16513 16483 16477>,
			<16883 16709 16607 16513 16491 16481>,
			<16900 16705 16600 16513 16489 16481>,
			<16916 16703 16596 16509 16482 16475>,
			<16897 16701 16609 16491 16461 16454>,
			<16825 16690 16612 16487 16467 16457>,
			<16840 16704 16629 16504 16482 16472>,
			<16853 16725 16657 16524 16497 16490>,
			<16864 16756 16686 16552 16519 16518>,
			<16872 16785 16726 16574 16531 16525>,
			<16864 16782 16740 16544 16483 16476>,
			<16849 16752 16709 16527 16475 16467>,
			<16857 16754 16716 16541 16481 16470>,
			<17031 16790 16753 16585 16514 16501>,
			<17031 16790 16753 16585 16514 16501>,
			<17031 16790 16753 16585 16514 16501>;
	};

	qcom,pc-temp-y5-lut {
		qcom,lut-col-legend = <(-10) 0 10 25 40 50>;
		qcom,lut-row-legend = <10000 9800 9600 9400 9200 9000>,
			<8800 8600 8400 8200 8000 7800>,
			<7600 7400 7200 7000 6800 6600>,
			<6400 6200 6000 5800 5600 5400>,
			<5200 5000 4800 4600 4400 4200>,
			<4000 3800 3600 3400 3200 3000>,
			<2800 2600 2400 2200 2000 1800>,
			<1600 1400 1200 1000 900 800>,
			<700 600 500 400 300 200>,
			<100 0>;
		qcom,lut-data = <13958 11779 13002 20302 17477 16219>,
			<13105 12296 13946 19298 17307 16828>,
			<12737 12882 15060 18235 17114 17303>,
			<12740 13446 16120 17222 16902 17641>,
			<13001 13895 16898 16372 16677 17841>,
			<13408 14137 17168 15796 16443 17900>,
			<14526 14171 17029 15386 16204 17791>,
			<15760 14184 16776 15117 15941 17573>,
			<15572 14499 16555 15161 15574 17322>,
			<14117 15340 16331 15467 15086 16979>,
			<13372 15738 16048 15623 14904 16554>,
			<14786 14800 15530 15162 15379 15825>,
			<16551 13661 15101 14450 15915 15225>,
			<16377 15416 15481 13983 15657 15382>,
			<14968 21637 16967 13591 14733 15958>,
			<13941 24339 18683 13476 14194 16124>,
			<13423 21405 21139 14074 13983 15193>,
			<13118 18195 22950 15234 13875 14288>,
			<13116 18436 23066 17410 13931 14274>,
			<13195 19853 23061 21052 14161 14381>,
			<13296 20360 22928 23123 14830 14742>,
			<13467 19213 22003 24058 18301 16803>,
			<13604 18060 20967 24546 21127 18472>,
			<13293 19021 20258 23544 20657 18385>,
			<12455 21401 19655 20973 19447 18094>,
			<12146 21708 19618 19786 18498 17851>,
			<12176 16731 20358 19430 17417 17556>,
			<12213 12286 20952 19258 16771 17265>,
			<12234 12053 20379 19558 16841 16679>,
			<12251 12204 19084 20337 17055 15991>,
			<12254 12298 18089 20776 17578 15884>,
			<12243 12382 16193 21052 19074 15905>,
			<12226 12475 15266 21309 19965 15959>,
			<12196 12602 15974 21877 19864 17277>,
			<12154 12800 17240 22785 19715 19135>,
			<12160 13043 18386 23015 19898 19578>,
			<12307 13349 19662 22798 20567 19725>,
			<12424 13643 20203 22426 20838 19751>,
			<12371 13956 20129 21466 20280 18520>,
			<12285 14249 19966 20147 19371 16994>,
			<12311 14257 19577 19446 18475 17200>,
			<12528 13838 18845 19053 17646 18274>,
			<12765 13349 18284 18507 17817 18281>,
			<13032 12969 16917 17852 17962 17790>,
			<13262 12926 13805 17842 17790 18448>,
			<13424 13131 13770 17976 16905 18188>,
			<13414 13228 13745 16675 15654 16595>,
			<13787 13381 13753 16520 16304 17422>,
			<14166 13672 14031 16238 17176 17117>,
			<14200 13937 14058 16707 17799 16813>,
			<14250 14092 14052 17293 18413 16885>,
			<13936 14109 13825 17585 17792 17880>,
			<13685 13930 13736 20102 21881 21686>,
			<12873 14027 13980 22116 25245 25435>,
			<12873 14027 13980 22116 25245 25435>,
			<12873 14027 13980 22116 25245 25435>;
	};

	qcom,pc-temp-y6-lut {
		qcom,lut-col-legend = <(-10) 0 10 25 40 50>;
		qcom,lut-row-legend = <10000 9800 9600 9400 9200 9000>,
			<8800 8600 8400 8200 8000 7800>,
			<7600 7400 7200 7000 6800 6600>,
			<6400 6200 6000 5800 5600 5400>,
			<5200 5000 4800 4600 4400 4200>,
			<4000 3800 3600 3400 3200 3000>,
			<2800 2600 2400 2200 2000 1800>,
			<1600 1400 1200 1000 900 800>,
			<700 600 500 400 300 200>,
			<100 0>;
		qcom,lut-data = <6531 5908 5343 5079 5018 5006>,
			<6463 5891 5344 5079 5018 5005>,
			<6398 5874 5344 5080 5019 5005>,
			<6337 5856 5344 5080 5020 5006>,
			<6284 5838 5344 5081 5021 5007>,
			<6240 5819 5344 5083 5023 5008>,
			<6206 5800 5340 5084 5024 5009>,
			<6176 5780 5335 5086 5026 5011>,
			<6141 5759 5334 5088 5028 5012>,
			<6101 5735 5333 5091 5030 5014>,
			<6084 5725 5332 5095 5032 5016>,
			<6096 5730 5334 5097 5035 5018>,
			<6111 5735 5337 5100 5039 5020>,
			<6088 5729 5343 5104 5042 5023>,
			<6001 5702 5354 5109 5045 5026>,
			<5959 5673 5357 5115 5049 5029>,
			<5961 5642 5332 5122 5054 5032>,
			<5963 5618 5306 5129 5058 5036>,
			<5962 5614 5299 5135 5064 5041>,
			<5959 5614 5297 5139 5071 5048>,
			<5956 5611 5291 5139 5071 5049>,
			<5954 5599 5276 5116 5059 5041>,
			<5951 5587 5263 5089 5043 5030>,
			<5949 5585 5258 5079 5031 5019>,
			<5947 5585 5255 5073 5021 5008>,
			<5947 5584 5254 5072 5019 5005>,
			<5955 5583 5255 5072 5020 5006>,
			<5967 5583 5256 5074 5021 5008>,
			<5976 5589 5255 5076 5024 5010>,
			<5987 5603 5254 5078 5028 5014>,
			<5999 5616 5255 5081 5032 5017>,
			<6013 5629 5260 5085 5037 5021>,
			<6030 5643 5267 5088 5040 5025>,
			<6048 5659 5275 5091 5040 5029>,
			<6067 5679 5287 5094 5040 5031>,
			<6090 5701 5299 5095 5039 5029>,
			<6118 5727 5315 5095 5035 5019>,
			<6149 5756 5332 5094 5031 5012>,
			<6183 5789 5351 5094 5029 5010>,
			<6220 5826 5370 5094 5027 5009>,
			<6260 5861 5390 5094 5028 5011>,
			<6305 5894 5413 5097 5031 5015>,
			<6354 5931 5437 5099 5031 5015>,
			<6404 5974 5461 5100 5029 5013>,
			<6431 6009 5462 5096 5021 5005>,
			<6404 6010 5489 5097 5026 5011>,
			<6451 6053 5520 5105 5032 5017>,
			<6514 6107 5559 5116 5041 5027>,
			<6572 6170 5604 5130 5052 5037>,
			<6635 6229 5649 5142 5057 5038>,
			<6702 6277 5689 5133 5038 5019>,
			<6786 6336 5736 5132 5035 5018>,
			<6916 6433 5867 5156 5043 5024>,
			<7363 6555 6050 5190 5060 5038>,
			<7363 6555 6050 5190 5060 5038>,
			<7363 6555 6050 5190 5060 5038>;
	};
};
